# CH32H417 register map
Vendor: WCH Ltd.; File version: 1.2
Registers are 32-bit, read-write, reset 0x0 unless marked. A register's access mark holds for its fields unless they carry their own. Offsets are from the block's base; [hi:lo] are bit positions; 'fields as' and 'values as' point back to an identical list.

## SWPMI — Single Wire Protocol Master Interface
Base 0x40008400
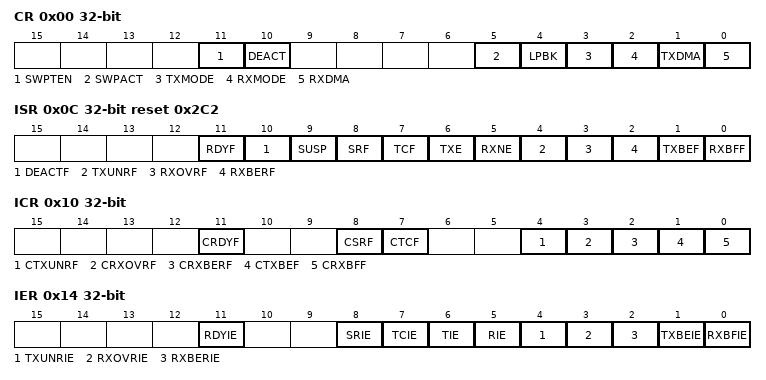
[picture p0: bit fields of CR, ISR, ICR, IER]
0x00 CR — SWPMI Configuration/Control register
  [11] SWPTEN — Single wire protocol master transceiver enable
  [10] DEACT — Single wire protocol master interface deactivate
  [5] SWPACT — Single wire protocol master interface activate
  [4] LPBK — Loopback mode enable
  [3] TXMODE — Transmission buffering mode
  [2] RXMODE — Reception buffering mode
  [1] TXDMA — Transmission DMA enable
  [0] RXDMA — Reception DMA enable
0x04 BRR reset 0x1 — SWPMI Bitrate register
  [7:0] BR — Bitrate prescaler
0x0C ISR ro reset 0x2C2 — SWPMI Interrupt and Status register
  [11] RDYF — transceiver ready flag
  [10] DEACTF — DEACTIVATED flag
  [9] SUSP — SUSPEND flag
  [8] SRF — Slave resume flag
  [7] TCF — Transfer complete flag
  [6] TXE — Transmit data register empty
  [5] RXNE — Receive data register not empty
  [4] TXUNRF — Transmit underrun error flag
  [3] RXOVRF — Receive overrun error flag
  [2] RXBERF — Receive CRC error flag
  [1] TXBEF — Transmit buffer empty flag
  [0] RXBFF — Receive buffer full flag
0x10 ICR — SWPMI Interrupt Flag Clear register
  [11] CRDYF — Clear transceiver ready flag
  [8] CSRF — Clear slave resume flag
  [7] CTCF — Clear transfer complete flag
  [4] CTXUNRF — Clear transmit underrun error flag
  [3] CRXOVRF — Clear receive overrun error flag
  [2] CRXBERF — Clear receive CRC error flag
  [1] CTXBEF — Clear transmit buffer empty flag
  [0] CRXBFF — Clear receive buffer full flag
0x14 IER — SWPMI Interrupt Enable register
  [11] RDYIE — Transceiver ready interrupt enable
  [8] SRIE — Slave resume interrupt enable
  [7] TCIE — Transmit complete interrupt enable
  [6] TIE — Transmit interrupt enable
  [5] RIE — Receive interrupt enable
  [4] TXUNRIE — Transmit underrun error interrupt enable
  [3] RXOVRIE — Receive overrun error interrupt enable
  [2] RXBERIE — Receive CRC error interrupt enable
  [1] TXBEIE — Transmit buffer empty interrupt enable
  [0] RXBFIE — Receive buffer full interrupt enable
0x18 RFL ro — SWPMI Receive Frame Length register
  [4:0] RFL — Receive frame length
0x1C TDR wo — SWPMI Transmit data register
  [31:0] TD — Transmit data
0x20 RDR ro — SWPMI Receive data register
  [31:0] RD — received data
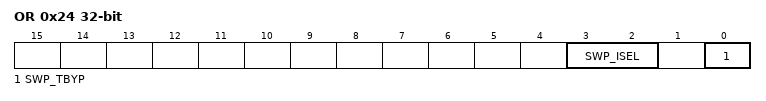
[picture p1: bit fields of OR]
0x24 OR — SWPMI Option register
  [3:2] SWP_ISEL — SWP current selection
  [0] SWP_TBYP — SWP transceiver bypass

## SAI
Base 0x40015800
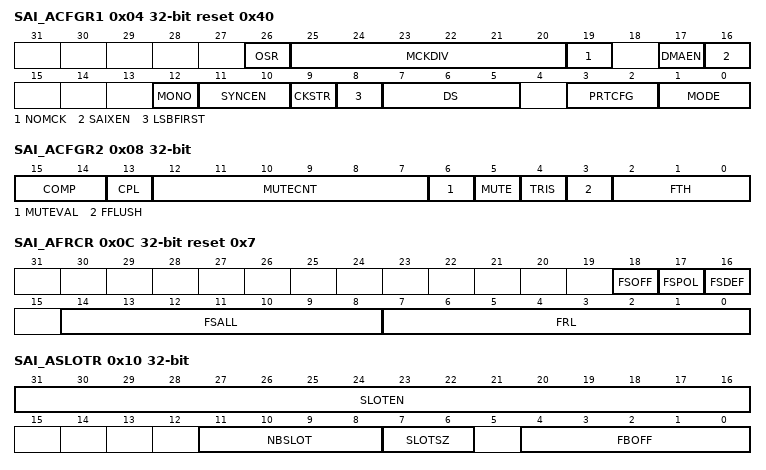
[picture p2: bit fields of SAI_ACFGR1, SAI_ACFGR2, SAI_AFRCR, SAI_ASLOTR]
0x04 SAI_ACFGR1 reset 0x40 — Configuration register 1
  [26] OSR — Oversampling ratio for master clock
  [25:20] MCKDIV — Master clock divider
  [19] NOMCK — No divider
  [17] DMAEN — DMA enable
  [16] SAIXEN — Audio block enable
  [12] MONO — Mono mode
  [11:10] SYNCEN — Synchronization enable
  [9] CKSTR — Clock strobing edge
  [8] LSBFIRST — Least significant bit first
  [7:5] DS — Data size
  [3:2] PRTCFG — Protocol configuration
  [1:0] MODE — SAIx audio block mode immediately
0x08 SAI_ACFGR2 — Configuration register 2
  [15:14] COMP — Companding mode
  [13] CPL — Complement bit
  [12:7] MUTECNT — Mute counter
  [6] MUTEVAL — Mute value
  [5] MUTE — Mute mode enable
  [4] TRIS — Tristate management on data line
  [3] FFLUSH — FIFO flush
  [2:0] FTH — FIFO threshold
0x0C SAI_AFRCR access per field reset 0x7 — This register has no meaning in AC97 and SPDIF audio protocol
  [18] FSOFF rw — Frame synchronization offset
  [17] FSPOL rw — Frame synchronization polarity
  [16] FSDEF ro — Frame synchronization definition
  [14:8] FSALL rw — Frame synchronization active level length
  [7:0] FRL rw — Frame length
0x10 SAI_ASLOTR — This register has no meaning in AC97 and SPDIF audio protocol
  [31:16] SLOTEN — Slot enable
  [11:8] NBSLOT — Number of slots in an audio frame
  [7:6] SLOTSZ — Slot size
  [4:0] FBOFF — First bit offset
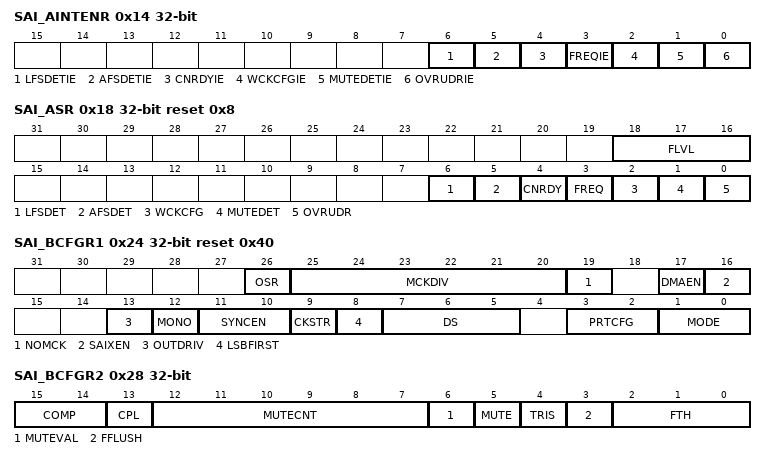
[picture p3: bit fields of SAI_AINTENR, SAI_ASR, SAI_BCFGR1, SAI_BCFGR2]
0x14 SAI_AINTENR — Interrupt mask register 2
  [6] LFSDETIE — Late frame synchronization detection interrupt enable
  [5] AFSDETIE — Anticipated frame synchronization detection interrupt enable
  [4] CNRDYIE — Codec not ready interrupt enable (AC97).
  [3] FREQIE — FIFO request interrupt enable
  [2] WCKCFGIE — Wrong clock configuration interrupt enable
  [1] MUTEDETIE — Mute detection interrupt enable
  [0] OVRUDRIE — Overrun/underrun interrupt enable
0x18 SAI_ASR access per field reset 0x8 — Status register
  [18:16] FLVL ro — FIFO level threshold
  [6] LFSDET rw — Late frame synchronization detection
  [5] AFSDET rw — Anticipated frame synchronization detection
  [4] CNRDY rw — Codec not ready
  [3] FREQ rw — FIFO request flag
  [2] WCKCFG rw — Wrong clock configuration error flag
  [1] MUTEDET rw — Mute detection flag
  [0] OVRUDR rw — Overrun/underrun error flag
0x20 SAI_ADATAR — Data register
  [31:0] DATA
0x24 SAI_BCFGR1 reset 0x40 — Configuration register 1
  [26] OSR — Oversampling ratio for master clock
  [25:20] MCKDIV — Master clock divider
  [19] NOMCK — No divider
  [17] DMAEN — DMA enable
  [16] SAIXEN — Audio block enable
  [13] OUTDRIV — Output drive
  [12] MONO — Mono mode
  [11:10] SYNCEN — Synchronization enable
  [9] CKSTR — Clock strobing edge
  [8] LSBFIRST — Least significant bit first
  [7:5] DS — Data size
  [3:2] PRTCFG — Protocol configuration
  [1:0] MODE — SAIx audio block mode immediately
0x28 SAI_BCFGR2 — Configuration register 2
  fields as SAI_ACFGR2
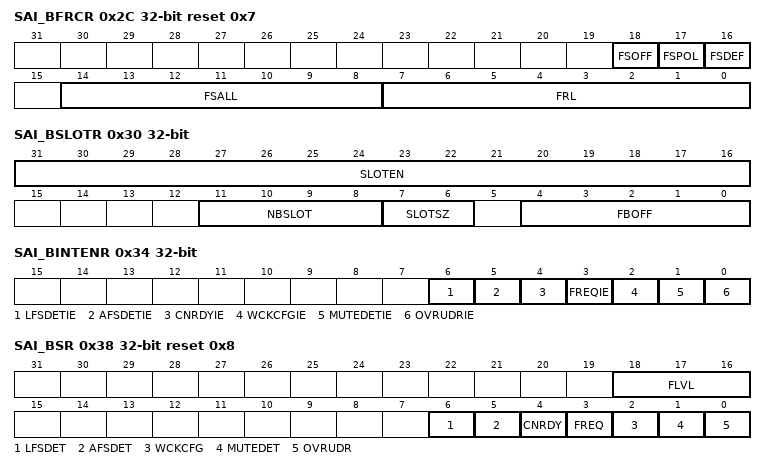
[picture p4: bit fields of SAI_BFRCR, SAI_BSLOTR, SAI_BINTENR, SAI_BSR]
0x2C SAI_BFRCR access per field reset 0x7 — This register has no meaning in AC97 and SPDIF audio protocol
  fields as SAI_AFRCR
0x30 SAI_BSLOTR — This register has no meaning in AC97 and SPDIF audio protocol
  fields as SAI_ASLOTR
0x34 SAI_BINTENR — Interrupt mask register 2
  fields as SAI_AINTENR
0x38 SAI_BSR access per field reset 0x8 — Status register
  fields as SAI_ASR
0x40 SAI_BDATAR — Data register
  [31:0] DATA
